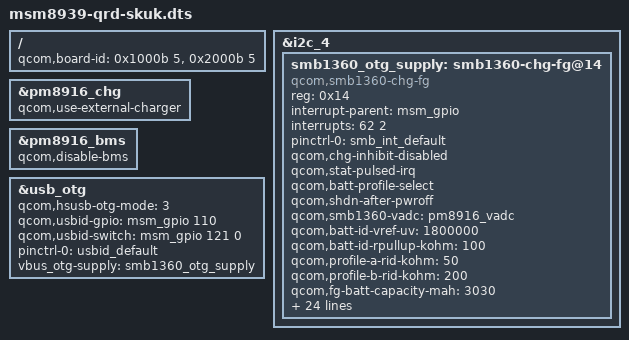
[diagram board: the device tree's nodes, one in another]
/* Copyright (c) 2014, The Linux Foundation. All rights reserved.
 *
 * This program is free software; you can redistribute it and/or modify
 * it under the terms of the GNU General Public License version 2 and
 * only version 2 as published by the Free Software Foundation.
 *
 * This program is distributed in the hope that it will be useful,
 * but WITHOUT ANY WARRANTY; without even the implied warranty of
 * MERCHANTABILITY or FITNESS FOR A PARTICULAR PURPOSE.  See the
 * GNU General Public License for more details.
 */

/dts-v1/;

#include "msm8939.dtsi"
#include "msm8939-qrd-skuk.dtsi"

/ {
	qcom,board-id = <0x1000b 5>, <0x2000b 5>;
};

&i2c_4 {
	smb1360_otg_supply: smb1360-chg-fg@14 {
		compatible = "qcom,smb1360-chg-fg";
		reg = <0x14>;
		interrupt-parent = <&msm_gpio>;
		interrupts = <62 2>;
		pinctrl-names = "default";
		pinctrl-0 = <&smb_int_default>;
		qcom,chg-inhibit-disabled;
		qcom,stat-pulsed-irq;

    /* battery-profile selection properties */
		qcom,batt-profile-select;
		qcom,shdn-after-pwroff;
		qcom,smb1360-vadc = <&pm8916_vadc>;
		qcom,batt-id-vref-uv = <1800000>;
		qcom,batt-id-rpullup-kohm = <100>;
		qcom,profile-a-rid-kohm = <50>;
		qcom,profile-b-rid-kohm = <200>;
		qcom,fg-batt-capacity-mah = <3030>;
		qcom,fg-cc-soc-coeff = <0x81C0>;
		qcom,fg-delta-soc = <1>;

		qcom,fg-cutoff-voltage-mv = <3450>;
		qcom,fg-iterm-ma = <100>;
		qcom,fg-ibatt-standby-ma = <200>;
		qcom,fg-cc-to-cv-mv = <4397>;
		qcom,thermistor-c1-coeff = <0x86C2>;

		qcom,float-voltage-mv = <4420>;
		qcom,iterm-ma = <100>;
		qcom,charging-timeout = <768>;
		qcom,fg-reset-at-pon;
		qcom,rsense-10mhom;
		qcom,fg-reset-thresold-mv = <200>;
		qcom,otg-batt-curr-limit = <1500>;
		qcom,recharge-thresh-mv = <50>;
		qcom,thermal-mitigation = <1500 700 600 0>;
		qcom,fg-auto-recharge-soc = <99>;
		qcom,empty-soc-disabled;
		regulator-name = "smb1360_otg_vreg";
		qcom,awake-min-soc;

		qcom,otp-jeita-cfg;
		qcom,config-hard-thresholds;
		qcom,hot-bat-decidegc = <550>;
		qcom,cold-bat-decidegc = <0>;//<(-150)>;
	};
};

&pm8916_chg {
	status = "ok";
	qcom,use-external-charger;
};

&pm8916_bms {
	status = "ok";
	qcom,disable-bms;
};

&usb_otg {
	qcom,hsusb-otg-mode = <3>;
	qcom,usbid-gpio = <&msm_gpio 110 0>;
	qcom,usbid-switch = <&msm_gpio 121 0>;
	pinctrl-names = "default";
	pinctrl-0 = <&usbid_default>;
	vbus_otg-supply = <&smb1360_otg_supply>;
};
